AUTOSAR XML (schema 4-2-2)
package /BMW/Platform/Vin/SwComponentTypes
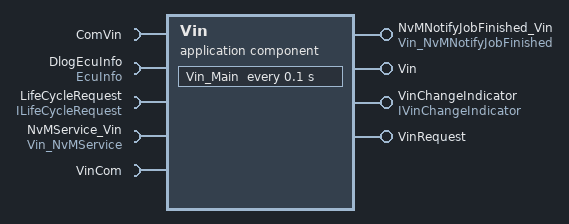
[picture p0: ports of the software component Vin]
  application sw component type Vin
    4 x provide port:
      NvMNotifyJobFinished_Vin: server-com-spec{operation=JobFinished, queue-length=1}, provided-interface=Vin_NvMNotifyJobFinished
      Vin: nonqueued-sender-com-spec{data-element=Vin, init-value={short-label=InitValue_Vin, fields=[Vin:7 x 0, Qualifier:0]}}, provided-interface=Vin
      VinChangeIndicator: mode-switch-sender-com-spec{enhanced-mode-api=false, mode-group=ChangeIndicator, mode-switched-ack=timeout=0, queue-length=1}, provided-interface=IVinChangeIndicator
      VinRequest: queued-sender-com-spec=data-element=RequestMessageIdentifier, provided-interface=VinRequest
    provide/require port LifeCycle: mode-switch-sender-com-spec{enhanced-mode-api=true, mode-group=Mode, queue-length=2}, mode-switch-receiver-com-spec{enhanced-mode-api=true, supports-asynchronous-mode-switch=false}, provided-required-interface=ILifeCycle
    5 x require port:
      ComVin: nonqueued-receiver-com-spec{data-element=ComVin, filter=data-filter-type=ALWAYS, init-value=fields=[Vin1:0, Vin2:0, Vin3:0, Vin4:0, Vin5:0, Vin6:0, Vin7:0]}, required-interface=ComVin
      DlogEcuInfo: required-com-specs=[GetEcuId, GetVin], required-interface=EcuInfo
      LifeCycleRequest: nonqueued-receiver-com-spec{data-element=requestMode, filter=data-filter-type=ALWAYS, init-value=2}, required-interface=ILifeCycleRequest
      NvMService_Vin: required-com-specs=[GetErrorStatus, ReadBlock, WriteBlock], required-interface=Vin_NvMService
      VinCom: mode-switch-receiver-com-spec{enhanced-mode-api=false, supports-asynchronous-mode-switch=false}, required-interface=VinCom
    behavior Vin_IB: data-type-mapping=dtms_VinLifeCycleMode
      exclusive area VinState
      data received event LifeCycleRequest: start-on-event=Vin_LifeCycleModeRequest, data=LifeCycleRequest.requestMode
      timing event Main: disabled-mode=[LifeCycle.Mode.VIN_INITIALIZED, LifeCycle.Mode.VIN_STOPPED, VinCom.Mode.VIN_VINCOMOFF], start-on-event=Vin_Main, period=0.1
      operation invoked event oie_NvMNotifyJobFinished_Vin_JobFinished: start-on-event=Vin_NvmJobFinished, operation=NvMNotifyJobFinished_Vin.JobFinished
      swc mode switch event mse_ComOff: start-on-event=Vin_OnComOff, activation=ON-TRANSITION, mode=[VinCom.Mode.VIN_VINCOMON, VinCom.Mode.VIN_VINCOMOFF]
      swc mode switch event mse_ComOn: start-on-event=Vin_OnComOn, activation=ON-TRANSITION, mode=[VinCom.Mode.VIN_VINCOMOFF, VinCom.Mode.VIN_VINCOMON]
      mode switched ack event msae_VinChangeIndicator: start-on-event=Vin_OnVinChangeIndicatorAck, event-source=mspVinChangeIndicator
      data received event dre_ComVin: start-on-event=Vin_ReceiveFromCom, data=ComVin.ComVin
      7 x runnable:
        Vin_LifeCycleModeRequest: runs-inside-exclusive-area=VinState, mode-access-point=LifeCycle.Mode
          data-read-access:
            access dra_requestMode: accessed-variable=LifeCycleRequest.requestMode
          mode switch point msp_LifeCycle: mode-group=LifeCycle.Mode
        Vin_Main: can-enter-exclusive-area=VinState
          data-send-points:
            access dsp_RequestMessageIdentifier: accessed-variable=VinRequest.RequestMessageIdentifier
          sync call scp_GetErrorStatus: operation=NvMService_Vin.GetErrorStatus, timeout=0
          sync call scp_ReadBlock: operation=NvMService_Vin.ReadBlock, timeout=0
        Vin_NvmJobFinished: can-enter-exclusive-area=VinState
          mode switch point msp_VinChangeIndicator: mode-group=VinChangeIndicator.ChangeIndicator
          sync call scp_WriteBlock: operation=NvMService_Vin.WriteBlock, timeout=0
        Vin_OnComOff
        Vin_OnComOn: runs-inside-exclusive-area=VinState
        Vin_OnVinChangeIndicatorAck: runs-inside-exclusive-area=VinState, mode-access-point=VinChangeIndicator.ChangeIndicator
          mode switch point mspVinChangeIndicator: mode-group=VinChangeIndicator.ChangeIndicator
          sync call scp_WriteBlock: operation=NvMService_Vin.WriteBlock, timeout=0
        Vin_ReceiveFromCom: can-enter-exclusive-area=VinState
          data-read-access:
            access dra_ComVin: accessed-variable=ComVin.ComVin
          data-send-points:
            access dsp_Vin: accessed-variable=Vin.Vin
          mode switch point msp_VinChangeIndicator: mode-group=VinChangeIndicator.ChangeIndicator
          sync call scp_GetVin: operation=DlogEcuInfo.GetVin, timeout=0
          sync call scp_WriteBlock: operation=NvMService_Vin.WriteBlock, timeout=0
  swc implementation Vin_Impl: behavior=Vin_IB
    code-descriptors:
      code Vin_Impl_Code: artifact-descriptors=autosar-engineering-object={short-label=Default, category=SWSRC}
